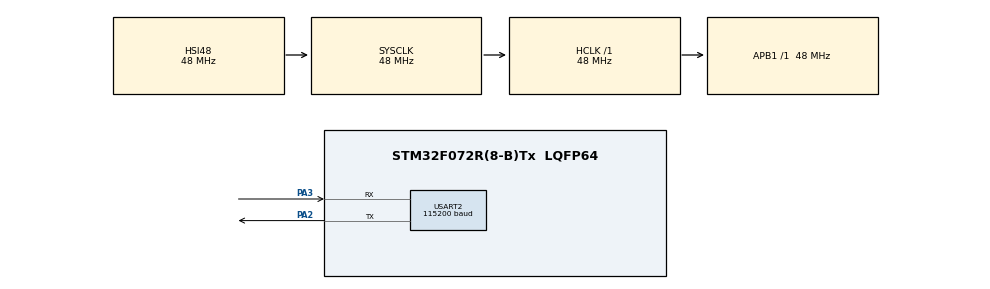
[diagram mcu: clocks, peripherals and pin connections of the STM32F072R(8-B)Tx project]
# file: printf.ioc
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Mcu.Family=STM32F0
Mcu.Name=STM32F072R(8-B)Tx
Mcu.Package=LQFP64
PA2.Mode=Asynchronous
PA2.Signal=USART2_TX
PA3.Mode=Asynchronous
PA3.Signal=USART2_RX
ProjectManager.HeapSize=0x200
ProjectManager.StackSize=0x400
ProjectManager.TargetToolchain=STM32CubeIDE
RCC.AHBFreq_Value=48000000
RCC.APB1Freq_Value=48000000
RCC.APB1TimFreq_Value=48000000
RCC.HCLKFreq_Value=48000000
RCC.SYSCLKFreq_VALUE=48000000
RCC.SYSCLKSource=RCC_SYSCLKSOURCE_HSI48
USART2.BaudRate=115200
USART2.VirtualMode-Asynchronous=VM_ASYNC
board=NUCLEO-F072RB

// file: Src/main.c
/* USER CODE BEGIN Header */
/**
  ******************************************************************************
  * @file           : main.c
  * @brief          : Main program body
  ******************************************************************************
  * @attention
  *
  * <h2><center>&copy; Copyright (c) 2019 STMicroelectronics.
  * All rights reserved.</center></h2>
  *
  * This software component is licensed by ST under BSD 3-Clause license,
  * the "License"; You may not use this file except in compliance with the
  * License. You may obtain a copy of the License at:
  *                        opensource.org/licenses/BSD-3-Clause
  *
  ******************************************************************************
  */
/* USER CODE END Header */

#include "main.h"

/* USER CODE BEGIN Includes */
#include <stdio.h>
#include "printf_override.h"
/* USER CODE END Includes */

UART_HandleTypeDef huart2;

void SystemClock_Config(void);
static void MX_GPIO_Init(void);
static void MX_USART2_UART_Init(void);

int main(void)
{

  /* MCU Configuration--------------------------------------------------------*/

  /* Reset of all peripherals, Initializes the Flash interface and the Systick. */
  HAL_Init();

  /* Configure the system clock */
  SystemClock_Config();

  /* Initialize all configured peripherals */
  MX_GPIO_Init();
  MX_USART2_UART_Init();

  /* Infinite loop */
  /* USER CODE BEGIN WHILE */
  while (1)
  {
	  printf("Hello World thru Included Override!\r\n");
	  HAL_Delay(1000);
    /* USER CODE END WHILE */
  }
}

void SystemClock_Config(void)
{
  RCC_OscInitTypeDef RCC_OscInitStruct = {0};
  RCC_ClkInitTypeDef RCC_ClkInitStruct = {0};
  RCC_PeriphCLKInitTypeDef PeriphClkInit = {0};

  /** Initializes the CPU, AHB and APB busses clocks
  */
  RCC_OscInitStruct.OscillatorType = RCC_OSCILLATORTYPE_HSI48;
  RCC_OscInitStruct.HSI48State = RCC_HSI48_ON;
  RCC_OscInitStruct.PLL.PLLState = RCC_PLL_NONE;
  if (HAL_RCC_OscConfig(&RCC_OscInitStruct) != HAL_OK)
  {
    Error_Handler();
  }
  /** Initializes the CPU, AHB and APB busses clocks
  */
  RCC_ClkInitStruct.ClockType = RCC_CLOCKTYPE_HCLK|RCC_CLOCKTYPE_SYSCLK
                              |RCC_CLOCKTYPE_PCLK1;
  RCC_ClkInitStruct.SYSCLKSource = RCC_SYSCLKSOURCE_HSI48;
  RCC_ClkInitStruct.AHBCLKDivider = RCC_SYSCLK_DIV1;
  RCC_ClkInitStruct.APB1CLKDivider = RCC_HCLK_DIV1;

  if (HAL_RCC_ClockConfig(&RCC_ClkInitStruct, FLASH_LATENCY_1) != HAL_OK)
  {
    Error_Handler();
  }
  PeriphClkInit.PeriphClockSelection = RCC_PERIPHCLK_USART2;
  PeriphClkInit.Usart2ClockSelection = RCC_USART2CLKSOURCE_PCLK1;
  if (HAL_RCCEx_PeriphCLKConfig(&PeriphClkInit) != HAL_OK)
  {
    Error_Handler();
  }
}

static void MX_USART2_UART_Init(void)
{

  huart2.Instance = USART2;
  huart2.Init.BaudRate = 115200;
  huart2.Init.WordLength = UART_WORDLENGTH_8B;
  huart2.Init.StopBits = UART_STOPBITS_1;
  huart2.Init.Parity = UART_PARITY_NONE;
  huart2.Init.Mode = UART_MODE_TX_RX;
  huart2.Init.HwFlowCtl = UART_HWCONTROL_NONE;
  huart2.Init.OverSampling = UART_OVERSAMPLING_16;
  huart2.Init.OneBitSampling = UART_ONE_BIT_SAMPLE_DISABLE;
  huart2.AdvancedInit.AdvFeatureInit = UART_ADVFEATURE_NO_INIT;
  if (HAL_UART_Init(&huart2) != HAL_OK)
  {
    Error_Handler();
  }

}

static void MX_GPIO_Init(void)
{

  /* GPIO Ports Clock Enable */
  __HAL_RCC_GPIOA_CLK_ENABLE();

}

void Error_Handler(void)
{
}

/************************ (C) COPYRIGHT STMicroelectronics *****END OF FILE****/
